# PIC32MX470F512H register map
Registers are 32-bit, access not given, reset 0x0 unless marked. A register's access mark holds for its fields unless they carry their own. Offsets are from the block's base; [hi:lo] are bit positions; {n}, {i} and the like mark numbered series; 'fields as' and 'values as' point back to an identical list.

## PORTG — PORTG peripheral
Base 0xBF886600
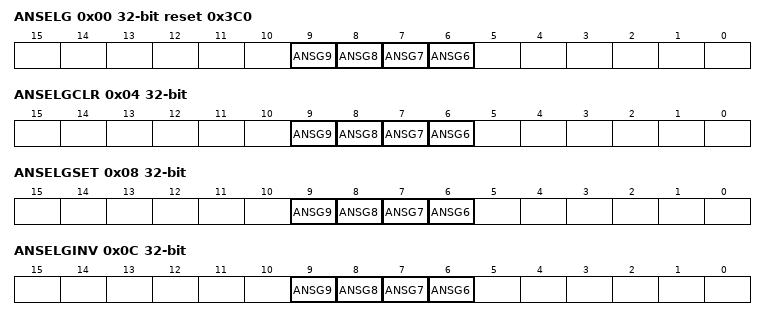
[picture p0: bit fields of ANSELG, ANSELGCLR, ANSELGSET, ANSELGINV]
0x00 ANSELG reset 0x3C0
  [n] ANSG{n} (n=6..9)
0x04 ANSELGCLR
  [n] ANSG{n} (n=6..9)
0x08 ANSELGSET
  [n] ANSG{n} (n=6..9)
0x0C ANSELGINV
  [n] ANSG{n} (n=6..9)
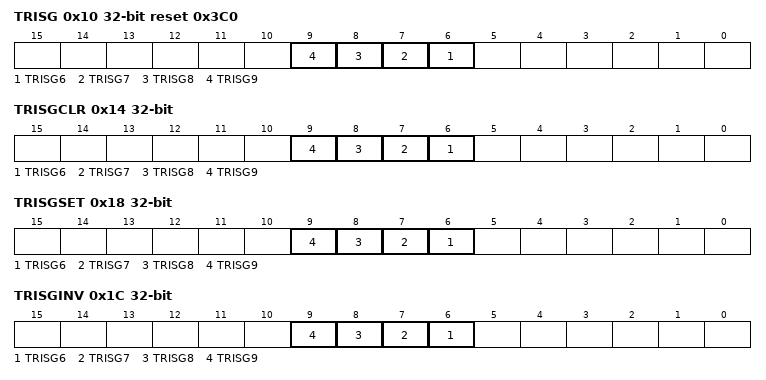
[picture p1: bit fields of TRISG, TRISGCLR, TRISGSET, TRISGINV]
0x10 TRISG reset 0x3C0
  [n] TRISG{n} (n=6..9)
0x14 TRISGCLR
  [n] TRISG{n} (n=6..9)
0x18 TRISGSET
  [n] TRISG{n} (n=6..9)
0x1C TRISGINV
  [n] TRISG{n} (n=6..9)
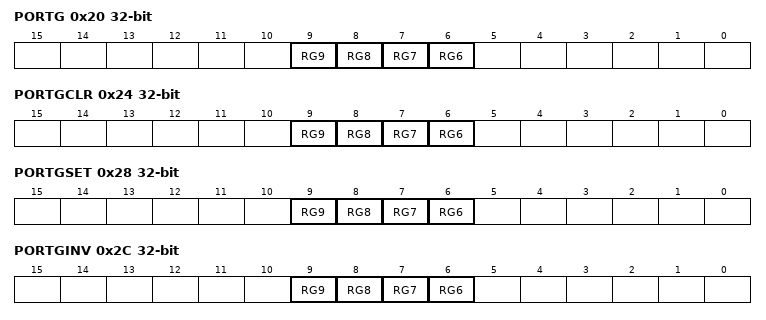
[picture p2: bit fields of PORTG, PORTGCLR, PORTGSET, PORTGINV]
0x20 PORTG
  [n] RG{n} (n=6..9)
0x24 PORTGCLR
  [n] RG{n} (n=6..9)
0x28 PORTGSET
  [n] RG{n} (n=6..9)
0x2C PORTGINV
  [n] RG{n} (n=6..9)
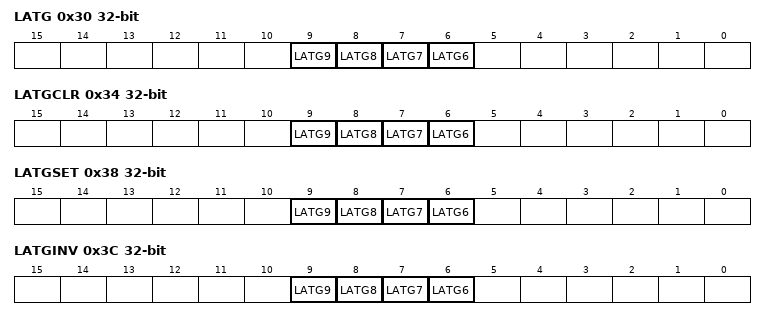
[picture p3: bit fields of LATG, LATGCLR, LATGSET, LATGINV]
0x30 LATG
  [n] LATG{n} (n=6..9)
0x34 LATGCLR
  [n] LATG{n} (n=6..9)
0x38 LATGSET
  [n] LATG{n} (n=6..9)
0x3C LATGINV
  [n] LATG{n} (n=6..9)
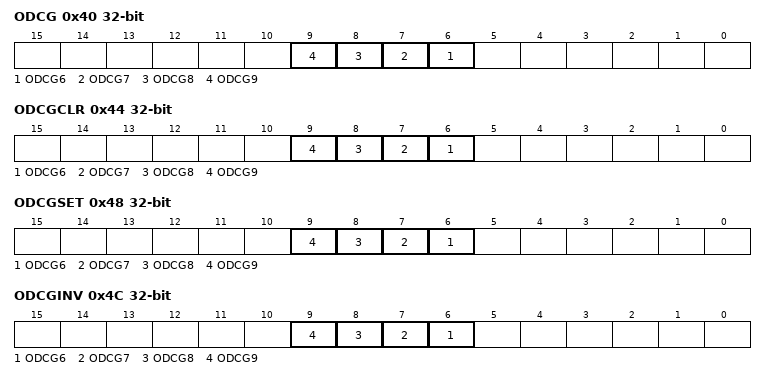
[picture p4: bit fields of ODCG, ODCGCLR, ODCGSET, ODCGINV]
0x40 ODCG
  [n] ODCG{n} (n=6..9)
0x44 ODCGCLR
  [n] ODCG{n} (n=6..9)
0x48 ODCGSET
  [n] ODCG{n} (n=6..9)
0x4C ODCGINV
  [n] ODCG{n} (n=6..9)
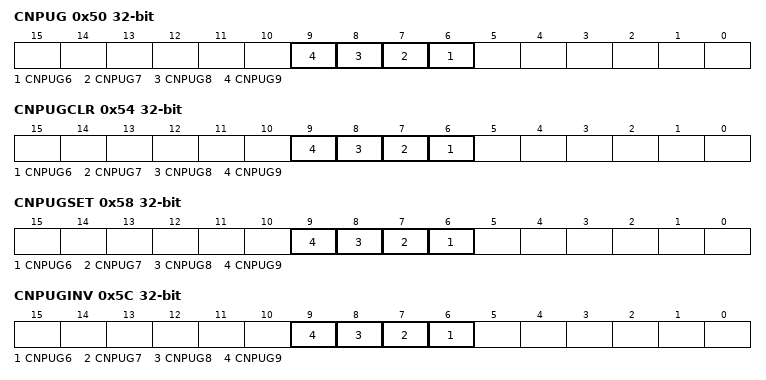
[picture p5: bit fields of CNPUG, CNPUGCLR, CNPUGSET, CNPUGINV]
0x50 CNPUG
  [n] CNPUG{n} (n=6..9)
0x54 CNPUGCLR
  [n] CNPUG{n} (n=6..9)
0x58 CNPUGSET
  [n] CNPUG{n} (n=6..9)
0x5C CNPUGINV
  [n] CNPUG{n} (n=6..9)
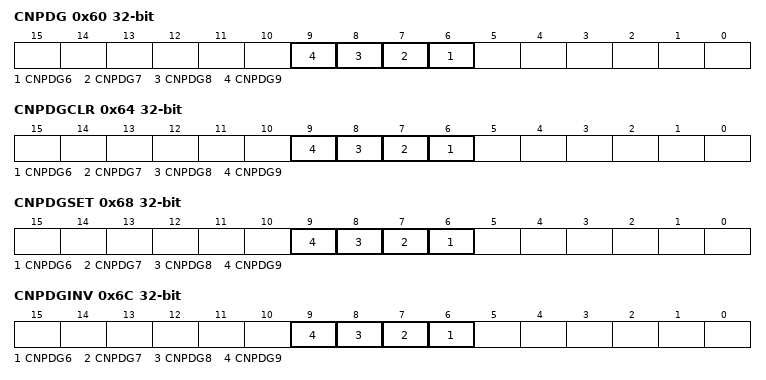
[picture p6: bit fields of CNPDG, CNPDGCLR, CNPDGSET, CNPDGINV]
0x60 CNPDG
  [n] CNPDG{n} (n=6..9)
0x64 CNPDGCLR
  [n] CNPDG{n} (n=6..9)
0x68 CNPDGSET
  [n] CNPDG{n} (n=6..9)
0x6C CNPDGINV
  [n] CNPDG{n} (n=6..9)
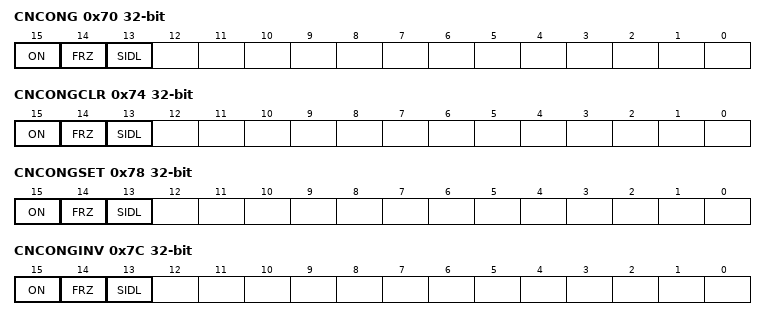
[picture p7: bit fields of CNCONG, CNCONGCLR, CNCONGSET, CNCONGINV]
0x70 CNCONG
  [15] ON, [14] FRZ, [13] SIDL
0x74 CNCONGCLR
  [15] ON, [14] FRZ, [13] SIDL
0x78 CNCONGSET
  [15] ON, [14] FRZ, [13] SIDL
0x7C CNCONGINV
  [15] ON, [14] FRZ, [13] SIDL
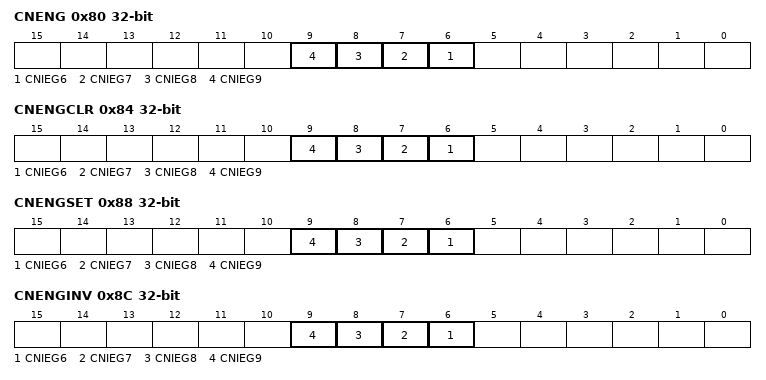
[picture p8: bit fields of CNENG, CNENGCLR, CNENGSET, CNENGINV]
0x80 CNENG
  [n] CNIEG{n} (n=6..9)
0x84 CNENGCLR
  [n] CNIEG{n} (n=6..9)
0x88 CNENGSET
  [n] CNIEG{n} (n=6..9)
0x8C CNENGINV
  [n] CNIEG{n} (n=6..9)
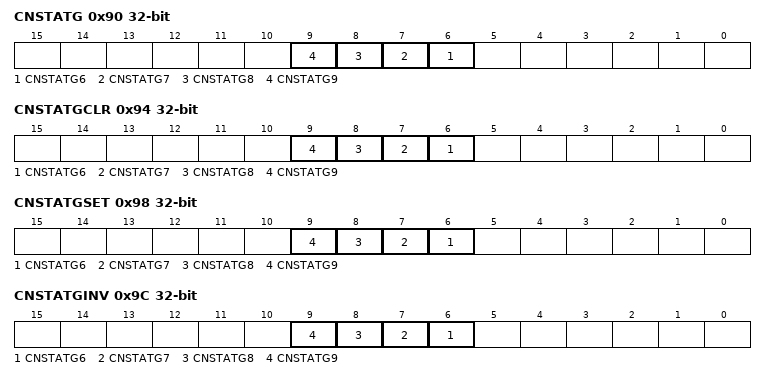
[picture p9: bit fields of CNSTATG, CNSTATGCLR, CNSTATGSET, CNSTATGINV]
0x90 CNSTATG
  [n] CNSTATG{n} (n=6..9)
0x94 CNSTATGCLR
  [n] CNSTATG{n} (n=6..9)
0x98 CNSTATGSET
  [n] CNSTATG{n} (n=6..9)
0x9C CNSTATGINV
  [n] CNSTATG{n} (n=6..9)

## WDT — WDT peripheral
Base 0xBF800000
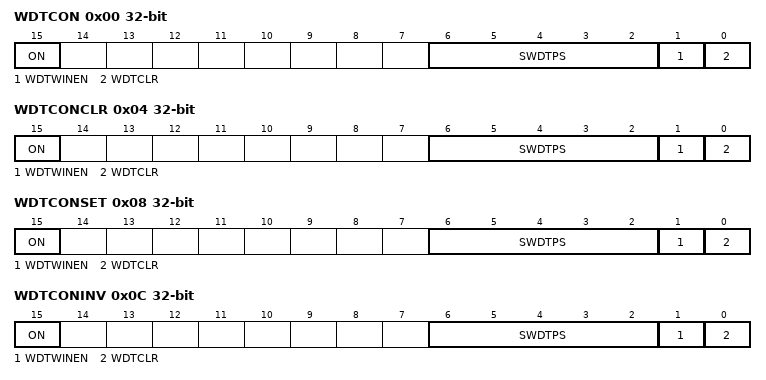
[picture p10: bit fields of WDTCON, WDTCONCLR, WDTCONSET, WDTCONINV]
0x00 WDTCON
  [15] ON, [6:2] SWDTPS, [1] WDTWINEN, [0] WDTCLR
0x04 WDTCONCLR
  [15] ON, [6:2] SWDTPS, [1] WDTWINEN, [0] WDTCLR
0x08 WDTCONSET
  [15] ON, [6:2] SWDTPS, [1] WDTWINEN, [0] WDTCLR
0x0C WDTCONINV
  [15] ON, [6:2] SWDTPS, [1] WDTWINEN, [0] WDTCLR

## RTCC — RTCC peripheral
Base 0xBF800200
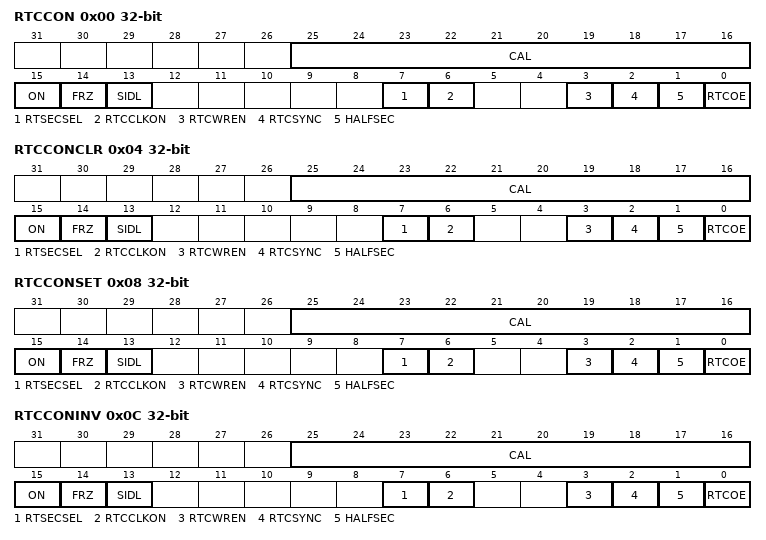
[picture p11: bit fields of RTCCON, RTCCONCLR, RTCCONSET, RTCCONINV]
0x00 RTCCON
  [25:16] CAL, [15] ON, [14] FRZ, [13] SIDL, [7] RTSECSEL, [6] RTCCLKON, [3] RTCWREN, [2] RTCSYNC, [1] HALFSEC, [0] RTCOE
0x04 RTCCONCLR
  fields as RTCCON
0x08 RTCCONSET
  fields as RTCCON
0x0C RTCCONINV
  fields as RTCCON
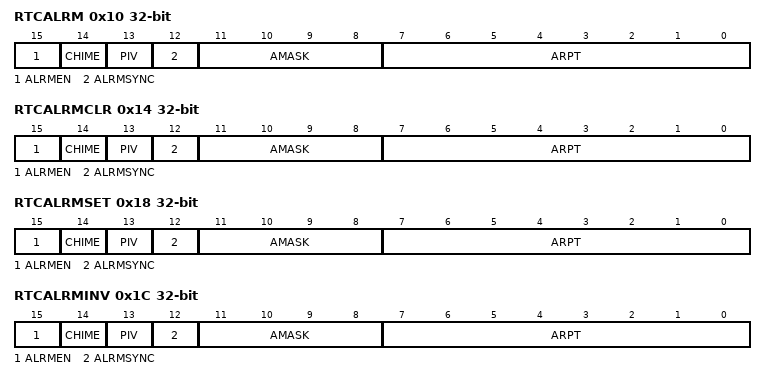
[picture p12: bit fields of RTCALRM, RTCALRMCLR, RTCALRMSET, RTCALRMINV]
0x10 RTCALRM
  [15] ALRMEN, [14] CHIME, [13] PIV, [12] ALRMSYNC, [11:8] AMASK, [7:0] ARPT
0x14 RTCALRMCLR
  fields as RTCALRM
0x18 RTCALRMSET
  fields as RTCALRM
0x1C RTCALRMINV
  fields as RTCALRM
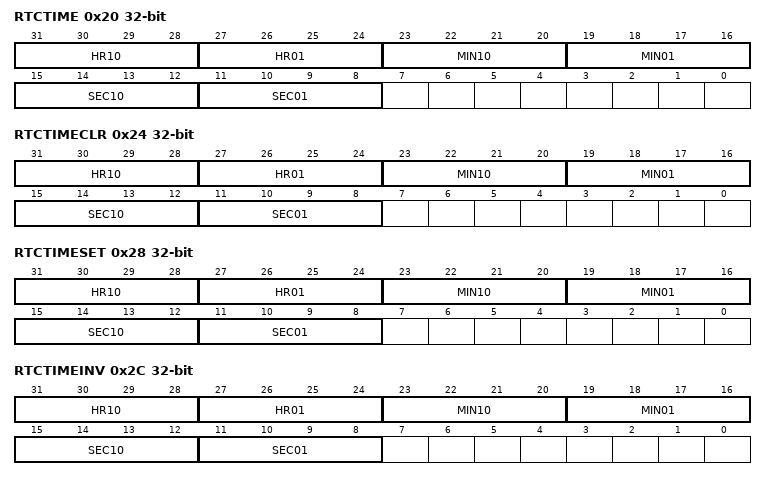
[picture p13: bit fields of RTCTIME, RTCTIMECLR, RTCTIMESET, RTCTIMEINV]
0x20 RTCTIME
  [31:28] HR10, [27:24] HR01, [23:20] MIN10, [19:16] MIN01, [15:12] SEC10, [11:8] SEC01
0x24 RTCTIMECLR
  fields as RTCTIME
0x28 RTCTIMESET
  fields as RTCTIME
0x2C RTCTIMEINV
  fields as RTCTIME
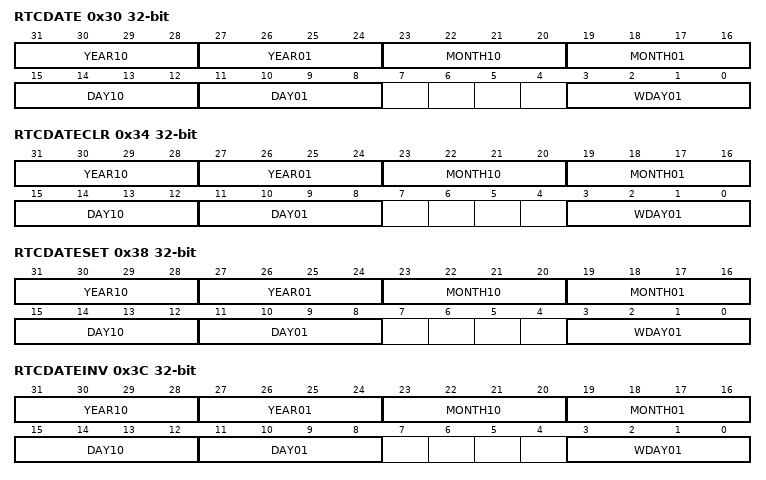
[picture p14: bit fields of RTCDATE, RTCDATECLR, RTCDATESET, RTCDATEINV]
0x30 RTCDATE
  [31:28] YEAR10, [27:24] YEAR01, [23:20] MONTH10, [19:16] MONTH01, [15:12] DAY10, [11:8] DAY01, [3:0] WDAY01
0x34 RTCDATECLR
  fields as RTCDATE
0x38 RTCDATESET
  fields as RTCDATE
0x3C RTCDATEINV
  fields as RTCDATE
0x40 ALRMTIME
  fields as RTCTIME
0x44 ALRMTIMECLR
  fields as RTCTIME
0x48 ALRMTIMESET
  fields as RTCTIME
0x4C ALRMTIMEINV
  fields as RTCTIME
0x50 ALRMDATE
  [23:20] MONTH10, [19:16] MONTH01, [15:12] DAY10, [11:8] DAY01, [3:0] WDAY01
0x54 ALRMDATECLR
  fields as ALRMDATE
0x58 ALRMDATESET
  fields as ALRMDATE
0x5C ALRMDATEINV
  fields as ALRMDATE

## TMR1 — TMR1 peripheral
Base 0xBF800600
0x00 T1CON
  [15] ON, [14] FRZ, [13] SIDL, [12] TWDIS, [11] TWIP, [7] TGATE, [5:4] TCKPS, [2] TSYNC, [1] TCS
0x04 T1CONCLR
  fields as T1CON
0x08 T1CONSET
  fields as T1CON
0x0C T1CONINV
  fields as T1CON
0x10 TMR1
0x14 TMR1CLR
  [31:0] TMR1
0x18 TMR1SET
  [31:0] TMR1
0x1C TMR1INV
  [31:0] TMR1
0x20 PR1 reset 0xFFFF
0x24 PR1CLR
  [31:0] PR1
0x28 PR1SET
  [31:0] PR1
0x2C PR1INV
  [31:0] PR1

## TMR2 — TMR2 peripheral
Base 0xBF800800
0x00 T2CON
  [15] ON, [14] FRZ, [13] SIDL, [7] TGATE, [6:4] TCKPS, [3] T32, [1] TCS
0x04 T2CONCLR
  fields as T2CON
0x08 T2CONSET
  fields as T2CON
0x0C T2CONINV
  fields as T2CON
0x10 TMR2
0x14 TMR2CLR
  [31:0] TMR2
0x18 TMR2SET
  [31:0] TMR2
0x1C TMR2INV
  [31:0] TMR2
0x20 PR2 reset 0xFFFF
0x24 PR2CLR
  [31:0] PR2
0x28 PR2SET
  [31:0] PR2
0x2C PR2INV
  [31:0] PR2
